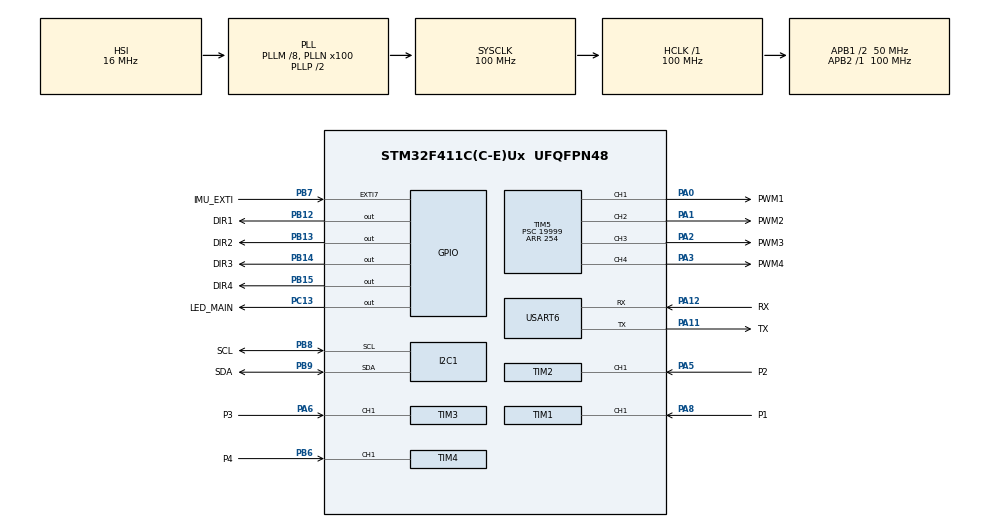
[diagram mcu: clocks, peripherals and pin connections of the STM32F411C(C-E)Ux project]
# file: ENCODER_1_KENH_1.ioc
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Dma.Request0=USART6_TX
Dma.Request1=USART6_RX
Dma.USART6_RX.1.Direction=DMA_PERIPH_TO_MEMORY
Dma.USART6_RX.1.FIFOMode=DMA_FIFOMODE_DISABLE
Dma.USART6_RX.1.Instance=DMA2_Stream1
Dma.USART6_RX.1.MemDataAlignment=DMA_MDATAALIGN_BYTE
Dma.USART6_RX.1.MemInc=DMA_MINC_ENABLE
Dma.USART6_RX.1.Mode=DMA_NORMAL
Dma.USART6_RX.1.PeriphDataAlignment=DMA_PDATAALIGN_BYTE
Dma.USART6_RX.1.PeriphInc=DMA_PINC_DISABLE
Dma.USART6_RX.1.Priority=DMA_PRIORITY_LOW
Dma.USART6_TX.0.Direction=DMA_MEMORY_TO_PERIPH
Dma.USART6_TX.0.FIFOMode=DMA_FIFOMODE_DISABLE
Dma.USART6_TX.0.Instance=DMA2_Stream6
Dma.USART6_TX.0.MemDataAlignment=DMA_MDATAALIGN_BYTE
Dma.USART6_TX.0.MemInc=DMA_MINC_ENABLE
Dma.USART6_TX.0.Mode=DMA_NORMAL
Dma.USART6_TX.0.PeriphDataAlignment=DMA_PDATAALIGN_BYTE
Dma.USART6_TX.0.PeriphInc=DMA_PINC_DISABLE
Dma.USART6_TX.0.Priority=DMA_PRIORITY_LOW
I2C1.I2C_Mode=I2C_Fast
Mcu.Family=STM32F4
Mcu.Name=STM32F411C(C-E)Ux
Mcu.Package=UFQFPN48
NVIC.DMA2_Stream1_IRQn=true\:0\:0\:false\:false\:true\:false\:true\:true
NVIC.DMA2_Stream6_IRQn=true\:0\:0\:false\:false\:true\:false\:true\:true
NVIC.EXTI9_5_IRQn=true\:0\:0\:false\:false\:true\:true\:true\:true
NVIC.PriorityGroup=NVIC_PRIORITYGROUP_4
NVIC.USART6_IRQn=true\:0\:0\:false\:false\:true\:true\:true\:true
PA0-WKUP.GPIO_Label=PWM1
PA0-WKUP.GPIO_Speed=GPIO_SPEED_FREQ_MEDIUM
PA0-WKUP.Signal=S_TIM5_CH1
PA1.GPIO_Label=PWM2
PA1.GPIO_Speed=GPIO_SPEED_FREQ_MEDIUM
PA1.Signal=S_TIM5_CH2
PA11.GPIO_Label=TX
PA11.GPIO_PuPd=GPIO_NOPULL
PA11.Mode=Asynchronous
PA11.Signal=USART6_TX
PA12.GPIO_Label=RX
PA12.GPIO_PuPd=GPIO_NOPULL
PA12.Mode=Asynchronous
PA12.Signal=USART6_RX
PA13.Mode=Serial_Wire
PA13.Signal=SYS_JTMS-SWDIO
PA14.Mode=Serial_Wire
PA14.Signal=SYS_JTCK-SWCLK
PA2.GPIO_Label=PWM3
PA2.GPIO_Speed=GPIO_SPEED_FREQ_MEDIUM
PA2.Signal=S_TIM5_CH3
PA3.GPIO_Label=PWM4
PA3.GPIO_Speed=GPIO_SPEED_FREQ_MEDIUM
PA3.Signal=S_TIM5_CH4
PA5.GPIO_Label=P2
PA5.GPIO_PuPd=GPIO_PULLDOWN
PA5.Signal=S_TIM2_CH1_ETR
PA6.GPIO_Label=P3
PA6.GPIO_PuPd=GPIO_PULLDOWN
PA6.Signal=S_TIM3_CH1
PA8.GPIO_Label=P1
PA8.GPIO_PuPd=GPIO_PULLDOWN
PA8.Signal=S_TIM1_CH1
PB12.GPIO_Label=DIR1
PB12.GPIO_Speed=GPIO_SPEED_FREQ_VERY_HIGH
PB12.Signal=GPIO_Output
PB13.GPIO_Label=DIR2
PB13.GPIO_Speed=GPIO_SPEED_FREQ_VERY_HIGH
PB13.Signal=GPIO_Output
PB14.GPIO_Label=DIR3
PB14.GPIO_Speed=GPIO_SPEED_FREQ_VERY_HIGH
PB14.Signal=GPIO_Output
PB15.GPIO_Label=DIR4
PB15.GPIO_Speed=GPIO_SPEED_FREQ_VERY_HIGH
PB15.Signal=GPIO_Output
PB6.GPIO_Label=P4
PB6.GPIO_PuPd=GPIO_PULLDOWN
PB6.Signal=S_TIM4_CH1
PB7.GPIO_Label=IMU_EXTI
PB7.GPIO_ModeDefaultEXTI=GPIO_MODE_IT_RISING
PB7.GPIO_PuPd=GPIO_PULLDOWN
PB7.Signal=GPXTI7
PB8.GPIO_Label=SCL
PB8.Mode=I2C
PB8.Signal=I2C1_SCL
PB9.GPIO_Label=SDA
PB9.Mode=I2C
PB9.Signal=I2C1_SDA
PC13-ANTI_TAMP.GPIO_Label=LED_MAIN
PC13-ANTI_TAMP.Signal=GPIO_Output
PH0\ -\ OSC_IN.Mode=HSE-External-Oscillator
PH0\ -\ OSC_IN.Signal=RCC_OSC_IN
PH1\ -\ OSC_OUT.Mode=HSE-External-Oscillator
PH1\ -\ OSC_OUT.Signal=RCC_OSC_OUT
ProjectManager.HeapSize=0x200
ProjectManager.StackSize=0x400
ProjectManager.TargetToolchain=EWARM V8.50
RCC.48MHZClocksFreq_Value=50000000
RCC.AHBFreq_Value=100000000
RCC.APB1CLKDivider=RCC_HCLK_DIV2
RCC.APB1Freq_Value=50000000
RCC.APB1TimFreq_Value=100000000
RCC.APB2Freq_Value=100000000
RCC.APB2TimFreq_Value=100000000
RCC.CortexFreq_Value=100000000
RCC.HCLKFreq_Value=100000000
RCC.HSE_VALUE=25000000
RCC.HSI_VALUE=16000000
RCC.LSE_VALUE=32768
RCC.PLLM=8
RCC.PLLN=100
RCC.SYSCLKFreq_VALUE=100000000
RCC.SYSCLKSource=RCC_SYSCLKSOURCE_PLLCLK
RCC.VCOOutputFreq_Value=200000000
SH.S_TIM1_CH1.0=TIM1_CH1,TriggerSource_TI1FP1
SH.S_TIM2_CH1_ETR.0=TIM2_CH1,TriggerSource_TI1FP1
SH.S_TIM3_CH1.0=TIM3_CH1,TriggerSource_TI1FP1
SH.S_TIM4_CH1.0=TIM4_CH1,TriggerSource_TI1FP1
SH.S_TIM5_CH1.0=TIM5_CH1,PWM Generation1 CH1
SH.S_TIM5_CH2.0=TIM5_CH2,PWM Generation2 CH2
SH.S_TIM5_CH3.0=TIM5_CH3,PWM Generation3 CH3
SH.S_TIM5_CH4.0=TIM5_CH4,PWM Generation4 CH4
TIM1.Slave_TriggerPolarity=TIM_TRIGGERPOLARITY_BOTHEDGE
TIM2.Slave_TriggerPolarity=TIM_TRIGGERPOLARITY_BOTHEDGE
TIM3.Slave_TriggerPolarity=TIM_TRIGGERPOLARITY_BOTHEDGE
TIM4.Slave_TriggerPolarity=TIM_TRIGGERPOLARITY_BOTHEDGE
TIM5.Channel-PWM\ Generation1\ CH1=TIM_CHANNEL_1
TIM5.Channel-PWM\ Generation2\ CH2=TIM_CHANNEL_2
TIM5.Channel-PWM\ Generation3\ CH3=TIM_CHANNEL_3
TIM5.Channel-PWM\ Generation4\ CH4=TIM_CHANNEL_4
TIM5.Period=254
TIM5.Prescaler=19999
TIM9.Prescaler=99
USART6.VirtualMode=VM_ASYNC
VP_TIM1_VS_ControllerModeClock.Mode=Clock Mode
VP_TIM2_VS_ControllerModeClock.Mode=Clock Mode
VP_TIM3_VS_ControllerModeClock.Mode=Clock Mode
VP_TIM4_VS_ControllerModeClock.Mode=Clock Mode
VP_TIM9_VS_ClockSourceINT.Mode=Internal
board=custom

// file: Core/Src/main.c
/* USER CODE BEGIN Header */
/**
  ******************************************************************************
  * @file           : main.c
  * @brief          : Main program body
  ******************************************************************************
  * @attention
  *
  * Copyright (c) 2026 STMicroelectronics.
  * All rights reserved.
  *
  * This software is licensed under terms that can be found in the LICENSE file
  * in the root directory of this software component.
  * If no LICENSE file comes with this software, it is provided AS-IS.
  *
  ******************************************************************************
  */
/* USER CODE END Header */
#include "main.h"
#include "dma.h"
#include "i2c.h"
#include "tim.h"
#include "usart.h"
#include "gpio.h"

/* USER CODE BEGIN Includes */
#include "main_cpp.hpp"
/* USER CODE END Includes */

void SystemClock_Config(void);

int main(void)
{

  /* MCU Configuration--------------------------------------------------------*/

  /* Reset of all peripherals, Initializes the Flash interface and the Systick. */
  HAL_Init();

  /* Configure the system clock */
  SystemClock_Config();

  /* Initialize all configured peripherals */
  MX_GPIO_Init();
  MX_DMA_Init();
  MX_TIM1_Init();
  MX_TIM2_Init();
  MX_TIM3_Init();
  MX_TIM4_Init();
  MX_TIM5_Init();
  MX_USART6_UART_Init();
  MX_I2C1_Init();
  MX_TIM9_Init();
  /* USER CODE BEGIN 2 */
  main_cpp();
  /* USER CODE END 2 */

  /* Infinite loop */
  while (1)
  {

  }
}

void SystemClock_Config(void)
{
  RCC_OscInitTypeDef RCC_OscInitStruct = {0};
  RCC_ClkInitTypeDef RCC_ClkInitStruct = {0};

  /** Configure the main internal regulator output voltage
  */
  __HAL_RCC_PWR_CLK_ENABLE();
  __HAL_PWR_VOLTAGESCALING_CONFIG(PWR_REGULATOR_VOLTAGE_SCALE1);

  /** Initializes the RCC Oscillators according to the specified parameters
  * in the RCC_OscInitTypeDef structure.
  */
  RCC_OscInitStruct.OscillatorType = RCC_OSCILLATORTYPE_HSI;
  RCC_OscInitStruct.HSIState = RCC_HSI_ON;
  RCC_OscInitStruct.HSICalibrationValue = RCC_HSICALIBRATION_DEFAULT;
  RCC_OscInitStruct.PLL.PLLState = RCC_PLL_ON;
  RCC_OscInitStruct.PLL.PLLSource = RCC_PLLSOURCE_HSI;
  RCC_OscInitStruct.PLL.PLLM = 8;
  RCC_OscInitStruct.PLL.PLLN = 100;
  RCC_OscInitStruct.PLL.PLLP = RCC_PLLP_DIV2;
  RCC_OscInitStruct.PLL.PLLQ = 4;
  if (HAL_RCC_OscConfig(&RCC_OscInitStruct) != HAL_OK)
  {
    Error_Handler();
  }

  /** Initializes the CPU, AHB and APB buses clocks
  */
  RCC_ClkInitStruct.ClockType = RCC_CLOCKTYPE_HCLK|RCC_CLOCKTYPE_SYSCLK
                              |RCC_CLOCKTYPE_PCLK1|RCC_CLOCKTYPE_PCLK2;
  RCC_ClkInitStruct.SYSCLKSource = RCC_SYSCLKSOURCE_PLLCLK;
  RCC_ClkInitStruct.AHBCLKDivider = RCC_SYSCLK_DIV1;
  RCC_ClkInitStruct.APB1CLKDivider = RCC_HCLK_DIV2;
  RCC_ClkInitStruct.APB2CLKDivider = RCC_HCLK_DIV1;

  if (HAL_RCC_ClockConfig(&RCC_ClkInitStruct, FLASH_LATENCY_3) != HAL_OK)
  {
    Error_Handler();
  }
}

void Error_Handler(void)
{
  __disable_irq();
  while (1)
  {
  }
}
